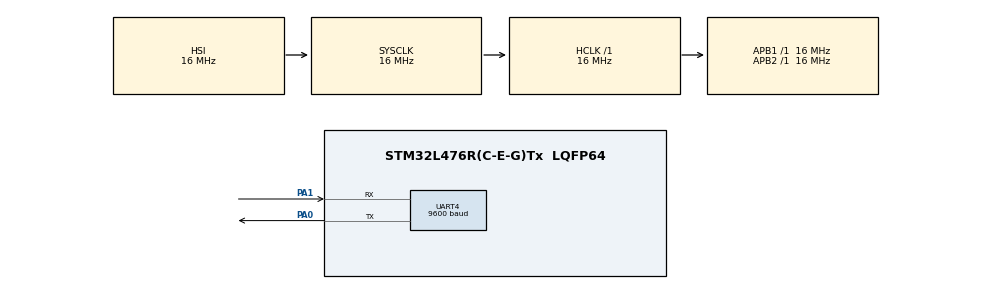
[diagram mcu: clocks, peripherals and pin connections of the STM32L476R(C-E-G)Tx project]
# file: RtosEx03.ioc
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FREERTOS.CountingSemaphores01=SemafaroCont,2,Dynamic,NULL,2
FREERTOS.Tasks01=tarefa2,24,128,tarefa2_fun,Default,NULL,Dynamic,NULL,NULL;tarefa1,24,128,tarefa1_fun,Default,NULL,Dynamic,NULL,NULL;tarefa3,24,128,tarefa3_fun,Default,NULL,Dynamic,NULL,NULL
FREERTOS.configUSE_NEWLIB_REENTRANT=1
Mcu.Family=STM32L4
Mcu.Name=STM32L476R(C-E-G)Tx
Mcu.Package=LQFP64
NVIC.PriorityGroup=NVIC_PRIORITYGROUP_4
NVIC.TIM1_UP_TIM16_IRQn=true\:15\:0\:false\:false\:true\:false\:false\:true\:true
NVIC.TimeBase=TIM1_UP_TIM16_IRQn
NVIC.TimeBaseIP=TIM1
PA0.Mode=Asynchronous
PA0.Signal=UART4_TX
PA1.Mode=Asynchronous
PA1.Signal=UART4_RX
ProjectManager.HeapSize=0x200
ProjectManager.StackSize=0x400
ProjectManager.TargetToolchain=STM32CubeIDE
RCC.ADCFreq_Value=64000000
RCC.AHBFreq_Value=16000000
RCC.APB1Freq_Value=16000000
RCC.APB1TimFreq_Value=16000000
RCC.APB2Freq_Value=16000000
RCC.APB2TimFreq_Value=16000000
RCC.CortexFreq_Value=16000000
RCC.HCLKFreq_Value=16000000
RCC.HSE_VALUE=8000000
RCC.HSI_VALUE=16000000
RCC.MSI_VALUE=4000000
RCC.PLLN=10
RCC.PLLSourceVirtual=RCC_PLLSOURCE_HSI
RCC.PREFETCH_ENABLE=1
RCC.SYSCLKFreq_VALUE=16000000
RCC.SYSCLKSource=RCC_SYSCLKSOURCE_HSI
RCC.USBFreq_Value=64000000
RCC.VCOOutputFreq_Value=160000000
UART4.BaudRate=9600
UART4.Mode=MODE_TX
VP_FREERTOS_VS_CMSIS_V2.Mode=CMSIS_V2
VP_SYS_VS_tim1.Mode=TIM1
board=NUCLEO-L476RG

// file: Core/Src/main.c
/* USER CODE BEGIN Header */
/**
  ******************************************************************************
  * @file           : main.c
  * @brief          : Main program body
  ******************************************************************************
  * @attention
  *
  * Copyright (c) 2025 STMicroelectronics.
  * All rights reserved.
  *
  * This software is licensed under terms that can be found in the LICENSE file
  * in the root directory of this software component.
  * If no LICENSE file comes with this software, it is provided AS-IS.
  *
  ******************************************************************************
  */
/* USER CODE END Header */
#include "main.h"
#include "cmsis_os.h"

/* USER CODE BEGIN PTD */
int8_t cont;
/* USER CODE END PTD */

UART_HandleTypeDef huart4;

/* Definitions for tarefa2 */
osThreadId_t tarefa2Handle;
const osThreadAttr_t tarefa2_attributes = {
  .name = "tarefa2",
  .stack_size = 128 * 4,
  .priority = (osPriority_t) osPriorityNormal,
};
/* Definitions for tarefa1 */
osThreadId_t tarefa1Handle;
const osThreadAttr_t tarefa1_attributes = {
  .name = "tarefa1",
  .stack_size = 128 * 4,
  .priority = (osPriority_t) osPriorityNormal,
};
/* Definitions for tarefa3 */
osThreadId_t tarefa3Handle;
const osThreadAttr_t tarefa3_attributes = {
  .name = "tarefa3",
  .stack_size = 128 * 4,
  .priority = (osPriority_t) osPriorityNormal,
};
/* Definitions for SemafaroCont */
osSemaphoreId_t SemafaroContHandle;
const osSemaphoreAttr_t SemafaroCont_attributes = {
  .name = "SemafaroCont"
};

void SystemClock_Config(void);
static void MX_GPIO_Init(void);
static void MX_UART4_Init(void);
void tarefa2_fun(void *argument);
void tarefa1_fun(void *argument);
void tarefa3_fun(void *argument);

int main(void)
{

  /* MCU Configuration--------------------------------------------------------*/

  /* Reset of all peripherals, Initializes the Flash interface and the Systick. */
  HAL_Init();

  /* Configure the system clock */
  SystemClock_Config();

  /* Initialize all configured peripherals */
  MX_GPIO_Init();
  MX_UART4_Init();

  /* Init scheduler */
  osKernelInitialize();

  /* Create the semaphores(s) */
  /* creation of SemafaroCont */
  SemafaroContHandle = osSemaphoreNew(2, 2, &SemafaroCont_attributes);

  /* Create the thread(s) */
  /* creation of tarefa2 */
  tarefa2Handle = osThreadNew(tarefa2_fun, NULL, &tarefa2_attributes);

  /* creation of tarefa1 */
  tarefa1Handle = osThreadNew(tarefa1_fun, NULL, &tarefa1_attributes);

  /* creation of tarefa3 */
  tarefa3Handle = osThreadNew(tarefa3_fun, NULL, &tarefa3_attributes);

  /* Start scheduler */
  osKernelStart();

  /* We should never get here as control is now taken by the scheduler */

  /* Infinite loop */
  while (1)
  {

  }
}

void SystemClock_Config(void)
{
  RCC_OscInitTypeDef RCC_OscInitStruct = {0};
  RCC_ClkInitTypeDef RCC_ClkInitStruct = {0};

  /** Configure the main internal regulator output voltage
  */
  if (HAL_PWREx_ControlVoltageScaling(PWR_REGULATOR_VOLTAGE_SCALE1) != HAL_OK)
  {
    Error_Handler();
  }

  /** Initializes the RCC Oscillators according to the specified parameters
  * in the RCC_OscInitTypeDef structure.
  */
  RCC_OscInitStruct.OscillatorType = RCC_OSCILLATORTYPE_HSI;
  RCC_OscInitStruct.HSIState = RCC_HSI_ON;
  RCC_OscInitStruct.HSICalibrationValue = RCC_HSICALIBRATION_DEFAULT;
  RCC_OscInitStruct.PLL.PLLState = RCC_PLL_NONE;
  if (HAL_RCC_OscConfig(&RCC_OscInitStruct) != HAL_OK)
  {
    Error_Handler();
  }

  /** Initializes the CPU, AHB and APB buses clocks
  */
  RCC_ClkInitStruct.ClockType = RCC_CLOCKTYPE_HCLK|RCC_CLOCKTYPE_SYSCLK
                              |RCC_CLOCKTYPE_PCLK1|RCC_CLOCKTYPE_PCLK2;
  RCC_ClkInitStruct.SYSCLKSource = RCC_SYSCLKSOURCE_HSI;
  RCC_ClkInitStruct.AHBCLKDivider = RCC_SYSCLK_DIV1;
  RCC_ClkInitStruct.APB1CLKDivider = RCC_HCLK_DIV1;
  RCC_ClkInitStruct.APB2CLKDivider = RCC_HCLK_DIV1;

  if (HAL_RCC_ClockConfig(&RCC_ClkInitStruct, FLASH_LATENCY_0) != HAL_OK)
  {
    Error_Handler();
  }
}

static void MX_UART4_Init(void)
{

  huart4.Instance = UART4;
  huart4.Init.BaudRate = 9600;
  huart4.Init.WordLength = UART_WORDLENGTH_8B;
  huart4.Init.StopBits = UART_STOPBITS_1;
  huart4.Init.Parity = UART_PARITY_NONE;
  huart4.Init.Mode = UART_MODE_TX;
  huart4.Init.HwFlowCtl = UART_HWCONTROL_NONE;
  huart4.Init.OverSampling = UART_OVERSAMPLING_16;
  huart4.Init.OneBitSampling = UART_ONE_BIT_SAMPLE_DISABLE;
  huart4.AdvancedInit.AdvFeatureInit = UART_ADVFEATURE_NO_INIT;
  if (HAL_UART_Init(&huart4) != HAL_OK)
  {
    Error_Handler();
  }

}

static void MX_GPIO_Init(void)
{

  /* GPIO Ports Clock Enable */
  __HAL_RCC_GPIOA_CLK_ENABLE();

}

void tarefa2_fun(void *argument)
{
  /* USER CODE BEGIN 5 */
  /* Infinite loop */
  for(;;)
  {
	  // Teste 1
//	  HAL_UART_Transmit(&huart4, "t2\r\n", 4, 100);
//	  osDelay(100);

	  // Teste 2
	  osSemaphoreAcquire(SemafaroContHandle, osWaitForever);
	  HAL_UART_Transmit(&huart4, "t2\r\n", 4, 100);
	  cont = osSemaphoreGetCount(SemafaroContHandle);
	  osDelay(100);
  }
  /* USER CODE END 5 */
}

void tarefa1_fun(void *argument)
{
  /* USER CODE BEGIN tarefa1_fun */
  /* Infinite loop */
  for(;;)
  {
	  // Teste 1
//	  cont = osSemaphoreGetCount(SemafaroContHandle); // qtd de recursos disponiveis
//
//	  osSemaphoreAcquire(SemafaroContHandle, osWaitForever); //requisitando um recurso
//	  HAL_UART_Transmit(&huart4, "t1\r\n", 4, 100);
//	  cont = osSemaphoreGetCount(SemafaroContHandle); // qtd de recursos disponiveis
//
//	  osSemaphoreRelease(SemafaroContHandle); // liberando recurso
//	  cont = osSemaphoreGetCount(SemafaroContHandle); // qtd de recursos disponiveis
//	  osDelay(100);

	  // Test 2
	  osSemaphoreAcquire(SemafaroContHandle, osWaitForever);
	  HAL_UART_Transmit(&huart4, "t1\r\n", 4, 100);
	  cont = osSemaphoreGetCount(SemafaroContHandle);
	  osDelay(100);

  }
  /* USER CODE END tarefa1_fun */
}

void tarefa3_fun(void *argument)
{
  /* USER CODE BEGIN tarefa3_fun */
  /* Infinite loop */
  for(;;)
  {
	  HAL_UART_Transmit(&huart4, "t3\r\n", 4, 100);
	  osDelay(100);
  }
  /* USER CODE END tarefa3_fun */
}

void HAL_TIM_PeriodElapsedCallback(TIM_HandleTypeDef *htim)
{
  if (htim->Instance == TIM1) {
    HAL_IncTick();
  }
}

void Error_Handler(void)
{
  __disable_irq();
  while (1)
  {
  }
}
